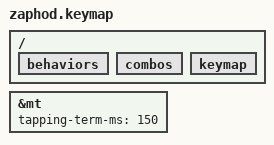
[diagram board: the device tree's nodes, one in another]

#include <behaviors.dtsi>
#include <dt-bindings/zmk/keys.h>
#include <dt-bindings/zmk/mouse.h>
#include <dt-bindings/zmk/bt.h>
#include <dt-bindings/zmk/reset.h>
#include <dt-bindings/zmk/outputs.h>

#define DEF_L 0
#define NUM_L 1
#define NAV_L 2
#define KBD_L 3
#define ALL_L 0 1 2 3

&mt {
  tapping-term-ms = <150>;
};

/ {
  behaviors {
#include "dtsi/behaviors.dtsi"
  };

  combos {
#include "dtsi/combos.dtsi"
  };

  keymap {
#include "dtsi/keymap.dtsi"
  };
};

#undef DEF_L NUM_L NAV_L KBD_L ALL_L
